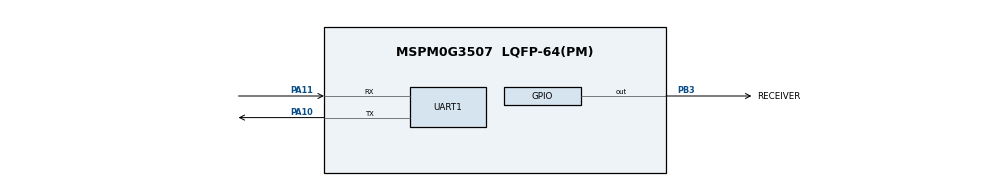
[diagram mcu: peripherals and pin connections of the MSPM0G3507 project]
//@cliArgs --device "MSPM0G350X" --package "LQFP-64(PM)" --part "Default"
//@v2CliArgs --device "MSPM0G3507" --package "LQFP-64(PM)"
// @cliArgs --board /ti/boards/LP_MSPM0G3507 --rtos nortos

/**
 * Import the modules used in this configuration.
 */
const GPIO   = scripting.addModule("/ti/driverlib/GPIO", {}, false);
const GPIO1  = GPIO.addInstance();
const GPIO2  = GPIO.addInstance();
const TIMER  = scripting.addModule("/ti/driverlib/TIMER", {}, false);
const TIMER1 = TIMER.addInstance();
const UART   = scripting.addModule("/ti/driverlib/UART", {}, false);
const UART1  = UART.addInstance();
const ProjectConfig = scripting.addModule("/ti/project_config/ProjectConfig", {}, false);

/**
 * Write custom configuration values to the imported modules.
 */
GPIO1.$name                          = "GPIO_LEDS";
GPIO1.associatedPins[0].$name        = "USER_LED_1";
GPIO1.associatedPins[0].assignedPort = "PORTA";
GPIO1.associatedPins[0].assignedPin  = "0";
GPIO1.associatedPins[0].initialValue = "SET";

const Board = scripting.addModule("/ti/driverlib/Board", {}, false);

GPIO2.$name                         = "GPIO_DE_TX";
GPIO2.associatedPins.create(2);
GPIO2.associatedPins[0].$name       = "TRANSMITTER";
GPIO2.associatedPins[1].$name       = "RECEIVER";
GPIO2.associatedPins[1].pin.$assign = "PB3";

const SYSCTL                 = scripting.addModule("/ti/driverlib/SYSCTL", {}, false);
SYSCTL.forceDefaultClkConfig = true;

TIMER1.$name       = "TIMER_0";
TIMER1.timerMode   = "PERIODIC";
TIMER1.timerClkSrc = "LFCLK";
TIMER1.timerPeriod = "100ms";

UART1.$name                    = "UART_0";
UART1.setExtDriverSetup        = 5;
UART1.setExtDriverHold         = 5;
UART1.enableFIFO               = true;
UART1.uartMode                 = "RS485";
UART1.stopBits                 = "TWO";
UART1.rxFifoThreshold          = "DL_UART_RX_FIFO_LEVEL_ONE_ENTRY";
UART1.txFifoThreshold          = "DL_UART_TX_FIFO_LEVEL_3_4_EMPTY";
UART1.enabledInterrupts        = ["OVERRUN_ERROR","RX"];
UART1.peripheral.$assign       = "UART0";
UART1.peripheral.rxPin.$assign = "PA11";
UART1.peripheral.txPin.$assign = "PA10";

ProjectConfig.genLibModbus = true;
